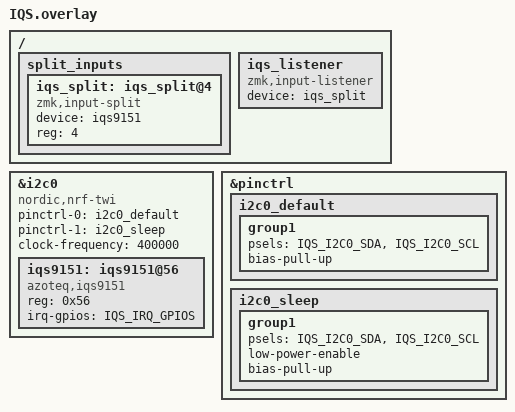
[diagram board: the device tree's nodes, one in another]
&i2c0 {
    status = "okay";
    compatible = "nordic,nrf-twi";
    pinctrl-0 = <&i2c0_default>;
    pinctrl-1 = <&i2c0_sleep>;
    pinctrl-names = "default", "sleep";
    clock-frequency = <400000>;

    iqs9151: iqs9151@56 {
        compatible = "azoteq,iqs9151";
        reg = <0x56>;
        status = "okay";
        irq-gpios = IQS_IRQ_GPIOS;
    };
};

&pinctrl {
    i2c0_default: i2c0_default {
        group1 {
            psels = <IQS_I2C0_SDA>,
                    <IQS_I2C0_SCL>;
            bias-pull-up;
        };
    };

    i2c0_sleep: i2c0_sleep {
        group1 {
            psels = <IQS_I2C0_SDA>,
                    <IQS_I2C0_SCL>;
            low-power-enable;
            bias-pull-up;
        };
    };
};

/ {
    split_inputs {
        #address-cells = <1>;
        #size-cells = <0>;

        iqs_split: iqs_split@4 {
            compatible = "zmk,input-split";
            status = "okay";
            device = <&iqs9151>;
            reg = <4>;
        };
    };

    iqs_listener: iqs_listener {
        compatible = "zmk,input-listener";
        status = "okay";
        device = <&iqs_split>;
    };
};
